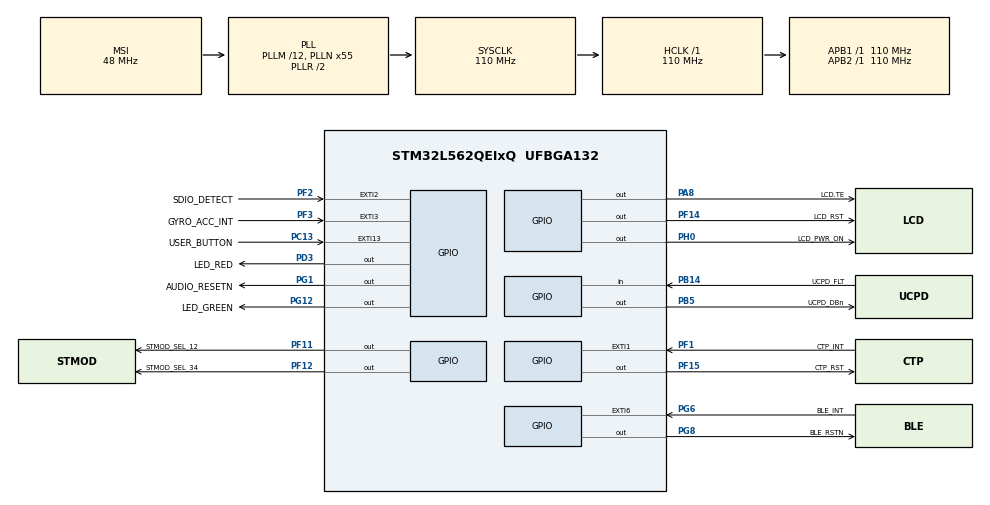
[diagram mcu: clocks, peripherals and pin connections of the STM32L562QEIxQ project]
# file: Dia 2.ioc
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Mcu.Family=STM32L5
Mcu.Name=STM32L562QEIxQ
Mcu.Package=UFBGA132
Mcu.TrustZone=disable
NVIC.EXTI13_IRQn=true\:0\:0\:false\:false\:true\:true\:true\:true
NVIC.PriorityGroup=NVIC_PRIORITYGROUP_3
NVIC.TIM2_IRQn=true\:0\:0\:false\:false\:true\:true\:true\:true
PA10.GPIO_Label=USART1_RX [ST-LINK_VCP_TX]
PA10.Signal=USART1_RX
PA11.Signal=USB_DM
PA12.Signal=USB_DP
PA13\ (JTMS/SWDIO).Signal=DEBUG_JTMS-SWDIO
PA14\ (JTCK/SWCLK).Signal=DEBUG_JTCK-SWCLK
PA15\ (JTDI).Signal=UCPD1_CC1
PA2.Signal=OCTOSPI1_NCS
PA3.Signal=OCTOSPI1_CLK
PA4.GPIO_Label=VBUS_SENSE
PA4.Signal=ADCx_IN9
PA6.Signal=OCTOSPI1_IO3
PA7.Signal=OCTOSPI1_IO2
PA8.GPIO_Label=LCD.TE
PA8.Signal=GPIO_Output
PA9.GPIO_Label=USART1_TX [ST-LINK_VCP_RX]
PA9.Signal=USART1_TX
PB0.Signal=OCTOSPI1_IO1
PB1.Signal=OCTOSPI1_IO0
PB10.Signal=LPUART1_RX
PB11.Signal=LPUART1_TX
PB12.Signal=S_DATAIN1DFSDM1
PB14.GPIO_Label=UCPD_FLT
PB14.Signal=GPIO_Input
PB15.Signal=UCPD1_CC2
PB2.Signal=OCTOSPI1_DQS
PB3\ (JTDO/TRACESWO).Signal=DEBUG_JTDO-SWO
PB5.GPIO_Label=UCPD_DBn
PB5.Signal=GPIO_Output
PB6.Signal=I2C1_SCL
PB7.Signal=I2C1_SDA
PC0.Signal=OCTOSPI1_IO7
PC1.Signal=OCTOSPI1_IO4
PC10.Signal=SDMMC1_D2
PC11.Signal=SDMMC1_D3
PC12.Signal=SDMMC1_CK
PC13.GPIO_Label=USER_BUTTON
PC13.GPIO_ModeDefaultEXTI=GPIO_MODE_IT_FALLING
PC13.Privilege=EXTI_LINE_NPRIV
PC13.Signal=GPXTI13
PC14-OSC32_IN\ (PC14).Signal=RCC_OSC32_IN
PC15-OSC32_OUT\ (PC15).Signal=RCC_OSC32_OUT
PC2.Signal=OCTOSPI1_IO5
PC3.Signal=OCTOSPI1_IO6
PC8.Signal=SDMMC1_D0
PC9.Signal=SDMMC1_D1
PD0.Signal=FMC_D2_DA2
PD1.Signal=FMC_D3_DA3
PD10.Signal=FMC_D15_DA15
PD14.Signal=FMC_D0_DA0
PD15.Signal=FMC_D1_DA1
PD2.Signal=SDMMC1_CMD
PD3.GPIO_Label=LED_RED
PD3.Signal=GPIO_Output
PD4.Signal=FMC_NOE
PD5.Signal=FMC_NWE
PD7.Signal=FMC_NE1
PD8.Signal=FMC_D13_DA13
PD9.Signal=FMC_D14_DA14
PE1.GPIO_Label=LCD_BL_PWM
PE1.Signal=S_TIM17_CH1
PE10.Signal=FMC_D7_DA7
PE11.Signal=FMC_D8_DA8
PE12.Signal=FMC_D9_DA9
PE13.Signal=FMC_D10_DA10
PE14.Signal=FMC_D11_DA11
PE15.Signal=FMC_D12_DA12
PE2.Signal=SAI1_MCLK_A
PE3.Signal=SAI1_SD_B
PE4.Signal=SAI1_FS_A
PE5.Signal=SAI1_SCK_A
PE6.Signal=SAI1_SD_A
PE7.Signal=FMC_D4_DA4
PE8.Signal=FMC_D5_DA5
PE9.Signal=FMC_D6_DA6
PF0.Signal=FMC_A0
PF1.GPIO_Label=CTP_INT
PF1.Signal=GPXTI1
PF11.GPIO_Label=STMOD_SEL_12
PF11.Signal=GPIO_Output
PF12.GPIO_Label=STMOD_SEL_34
PF12.Signal=GPIO_Output
PF14.GPIO_Label=LCD_RST
PF14.Signal=GPIO_Output
PF15.GPIO_Label=CTP_RST
PF15.Signal=GPIO_Output
PF2.GPIO_Label=SDIO_DETECT
PF2.Signal=GPXTI2
PF3.GPIO_Label=GYRO_ACC_INT
PF3.Signal=GPXTI3
PG1.GPIO_Label=AUDIO_RESETN
PG1.Signal=GPIO_Output
PG12.GPIO_Label=LED_GREEN
PG12.Signal=GPIO_Output
PG2.Signal=SPI1_SCK
PG3.Signal=SPI1_MISO
PG4.Signal=SPI1_MOSI
PG5.GPIO_Label=BLE_CSN
PG5.Signal=SPI1_NSS
PG6.GPIO_Label=BLE_INT
PG6.Signal=GPXTI6
PG7.Signal=S_CKOUTDFSDM1
PG8.GPIO_Label=BLE_RSTN
PG8.Signal=GPIO_Output
PH0-OSC_IN\ (PH0).GPIO_Label=LCD_PWR_ON
PH0-OSC_IN\ (PH0).Signal=GPIO_Output
ProjectManager.HeapSize=0x200
ProjectManager.StackSize=0x400
ProjectManager.TargetToolchain=STM32CubeIDE
RCC.ADCFreq_Value=96000000
RCC.AHBFreq_Value=110000000
RCC.APB1Freq_Value=110000000
RCC.APB1TimFreq_Value=110000000
RCC.APB2Freq_Value=110000000
RCC.APB2TimFreq_Value=110000000
RCC.CK48CLockSelection=RCC_USBCLKSOURCE_MSI
RCC.CortexFreq_Value=110000000
RCC.HCLKFreq_Value=110000000
RCC.HSE_VALUE=8000000
RCC.HSI48_VALUE=48000000
RCC.HSI_VALUE=16000000
RCC.LSE_VALUE=32768
RCC.MSIClockRange=RCC_MSIRANGE_11
RCC.MSI_VALUE=48000000
RCC.PLLM=12
RCC.PLLN=55
RCC.PLLSAI1M=4
RCC.PLLSAI1N=48
RCC.PLLSAI1P=RCC_PLLP_DIV17
RCC.PLLSAI1Source=RCC_PLLSAI1SOURCE_HSI
RCC.SDMMCClockSelection=RCC_SDIOCLKSOURCE_CLK48
RCC.SYSCLKFreq_VALUE=110000000
RCC.SYSCLKSource=RCC_SYSCLKSOURCE_PLLCLK
RCC.USBFreq_Value=48000000
RCC.VCOOutputFreq_Value=220000000
SH.ADCx_IN9.0=ADC1_IN9
SH.FMC_A0.0=FMC_A0
SH.FMC_D0_DA0.0=FMC_DA0
SH.FMC_D0_DA0.1=FMC_D0
SH.FMC_D10_DA10.0=FMC_DA10
SH.FMC_D10_DA10.1=FMC_D10
SH.FMC_D11_DA11.0=FMC_DA11
SH.FMC_D11_DA11.1=FMC_D11
SH.FMC_D12_DA12.0=FMC_DA12
SH.FMC_D12_DA12.1=FMC_D12
SH.FMC_D13_DA13.0=FMC_DA13
SH.FMC_D13_DA13.1=FMC_D13
SH.FMC_D14_DA14.0=FMC_DA14
SH.FMC_D14_DA14.1=FMC_D14
SH.FMC_D15_DA15.0=FMC_DA15
SH.FMC_D15_DA15.1=FMC_D15
SH.FMC_D1_DA1.0=FMC_DA1
SH.FMC_D1_DA1.1=FMC_D1
SH.FMC_D2_DA2.0=FMC_DA2
SH.FMC_D2_DA2.1=FMC_D2
SH.FMC_D3_DA3.0=FMC_DA3
SH.FMC_D3_DA3.1=FMC_D3
SH.FMC_D4_DA4.0=FMC_DA4
SH.FMC_D4_DA4.1=FMC_D4
SH.FMC_D5_DA5.0=FMC_DA5
SH.FMC_D5_DA5.1=FMC_D5
SH.FMC_D6_DA6.0=FMC_DA6
SH.FMC_D6_DA6.1=FMC_D6
SH.FMC_D7_DA7.0=FMC_DA7
SH.FMC_D7_DA7.1=FMC_D7
SH.FMC_D8_DA8.0=FMC_DA8
SH.FMC_D8_DA8.1=FMC_D8
SH.FMC_D9_DA9.0=FMC_DA9
SH.FMC_D9_DA9.1=FMC_D9
SH.FMC_NOE.0=FMC_NOE
SH.FMC_NWE.0=FMC_NWE
SH.S_CKOUTDFSDM1.0=DFSDM1_CKOUT
SH.S_DATAIN1DFSDM1.0=DFSDM1_DATIN1
SH.S_TIM17_CH1.0=TIM17_CH1
TIM2.Period=21999
TIM2.Prescaler=9999
VP_ICACHE_VS_ICACHE.Mode=DirectMappedCache
VP_PWR_VS_DBSignals.Mode=DisableDeadBatterySignals
VP_PWR_VS_SECSignals.Mode=Security/Privilege
VP_TIM2_VS_ClockSourceINT.Mode=Internal
board=STM32L562E-DK

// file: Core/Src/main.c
/* USER CODE BEGIN Header */
/**
  ******************************************************************************
  * @file           : main.c
  * @brief          : Main program body
  ******************************************************************************
  * @attention
  *
  * Copyright (c) 2025 STMicroelectronics.
  * All rights reserved.
  *
  * This software is licensed under terms that can be found in the LICENSE file
  * in the root directory of this software component.
  * If no LICENSE file comes with this software, it is provided AS-IS.
  *
  ******************************************************************************
  */
/* USER CODE END Header */
#include "main.h"

TIM_HandleTypeDef htim2;

void SystemClock_Config(void);
static void MX_GPIO_Init(void);
static void MX_ICACHE_Init(void);
static void MX_TIM2_Init(void);

int main(void)
{

  /* MCU Configuration--------------------------------------------------------*/

  /* Reset of all peripherals, Initializes the Flash interface and the Systick. */
  HAL_Init();

  /* Configure the system clock */
  SystemClock_Config();

  /* Initialize all configured peripherals */
  MX_GPIO_Init();
  MX_ICACHE_Init();
  MX_TIM2_Init();
  /* USER CODE BEGIN 2 */
  if (HAL_TIM_Base_Start_IT(&htim2) != HAL_OK) {
    Error_Handler();
  }
  /* USER CODE END 2 */

  /* Infinite loop */
  while (1)
  {

  }
}
void HAL_GPIO_EXTI_Falling_Callback(uint16_t GPIO_Pin)
{
    if (GPIO_Pin == USER_BUTTON_Pin) {
        HAL_GPIO_TogglePin(LED_RED_GPIO_Port, LED_RED_Pin); // LED2 enciende/apaga
    }
}
void HAL_TIM_PeriodElapsedCallback(TIM_HandleTypeDef *htim){
	if(htim->Instance==TIM2){
		HAL_GPIO_TogglePin(LED_GREEN_GPIO_Port, LED_GREEN_Pin);
	}
}
void SystemClock_Config(void)
{
  RCC_OscInitTypeDef RCC_OscInitStruct = {0};
  RCC_ClkInitTypeDef RCC_ClkInitStruct = {0};

  /** Configure the main internal regulator output voltage
  */
  if (HAL_PWREx_ControlVoltageScaling(PWR_REGULATOR_VOLTAGE_SCALE0) != HAL_OK)
  {
    Error_Handler();
  }

  /** Initializes the RCC Oscillators according to the specified parameters
  * in the RCC_OscInitTypeDef structure.
  */
  RCC_OscInitStruct.OscillatorType = RCC_OSCILLATORTYPE_MSI;
  RCC_OscInitStruct.MSIState = RCC_MSI_ON;
  RCC_OscInitStruct.MSICalibrationValue = RCC_MSICALIBRATION_DEFAULT;
  RCC_OscInitStruct.MSIClockRange = RCC_MSIRANGE_11;
  RCC_OscInitStruct.PLL.PLLState = RCC_PLL_ON;
  RCC_OscInitStruct.PLL.PLLSource = RCC_PLLSOURCE_MSI;
  RCC_OscInitStruct.PLL.PLLM = 12;
  RCC_OscInitStruct.PLL.PLLN = 55;
  RCC_OscInitStruct.PLL.PLLP = RCC_PLLP_DIV7;
  RCC_OscInitStruct.PLL.PLLQ = RCC_PLLQ_DIV2;
  RCC_OscInitStruct.PLL.PLLR = RCC_PLLR_DIV2;
  if (HAL_RCC_OscConfig(&RCC_OscInitStruct) != HAL_OK)
  {
    Error_Handler();
  }

  /** Initializes the CPU, AHB and APB buses clocks
  */
  RCC_ClkInitStruct.ClockType = RCC_CLOCKTYPE_HCLK|RCC_CLOCKTYPE_SYSCLK
                              |RCC_CLOCKTYPE_PCLK1|RCC_CLOCKTYPE_PCLK2;
  RCC_ClkInitStruct.SYSCLKSource = RCC_SYSCLKSOURCE_PLLCLK;
  RCC_ClkInitStruct.AHBCLKDivider = RCC_SYSCLK_DIV1;
  RCC_ClkInitStruct.APB1CLKDivider = RCC_HCLK_DIV1;
  RCC_ClkInitStruct.APB2CLKDivider = RCC_HCLK_DIV1;

  if (HAL_RCC_ClockConfig(&RCC_ClkInitStruct, FLASH_LATENCY_5) != HAL_OK)
  {
    Error_Handler();
  }
}

static void MX_ICACHE_Init(void)
{

  /** Enable instruction cache in 1-way (direct mapped cache)
  */
  if (HAL_ICACHE_ConfigAssociativityMode(ICACHE_1WAY) != HAL_OK)
  {
    Error_Handler();
  }
  if (HAL_ICACHE_Enable() != HAL_OK)
  {
    Error_Handler();
  }

}

static void MX_TIM2_Init(void)
{

  TIM_ClockConfigTypeDef sClockSourceConfig = {0};
  TIM_MasterConfigTypeDef sMasterConfig = {0};

  htim2.Instance = TIM2;
  htim2.Init.Prescaler = 9999;
  htim2.Init.CounterMode = TIM_COUNTERMODE_UP;
  htim2.Init.Period = 21999;
  htim2.Init.ClockDivision = TIM_CLOCKDIVISION_DIV1;
  htim2.Init.AutoReloadPreload = TIM_AUTORELOAD_PRELOAD_DISABLE;
  if (HAL_TIM_Base_Init(&htim2) != HAL_OK)
  {
    Error_Handler();
  }
  sClockSourceConfig.ClockSource = TIM_CLOCKSOURCE_INTERNAL;
  if (HAL_TIM_ConfigClockSource(&htim2, &sClockSourceConfig) != HAL_OK)
  {
    Error_Handler();
  }
  sMasterConfig.MasterOutputTrigger = TIM_TRGO_RESET;
  sMasterConfig.MasterSlaveMode = TIM_MASTERSLAVEMODE_DISABLE;
  if (HAL_TIMEx_MasterConfigSynchronization(&htim2, &sMasterConfig) != HAL_OK)
  {
    Error_Handler();
  }

}

static void MX_GPIO_Init(void)
{
  GPIO_InitTypeDef GPIO_InitStruct = {0};

  /* GPIO Ports Clock Enable */
  __HAL_RCC_GPIOE_CLK_ENABLE();
  __HAL_RCC_GPIOB_CLK_ENABLE();
  __HAL_RCC_GPIOG_CLK_ENABLE();
  HAL_PWREx_EnableVddIO2();
  __HAL_RCC_GPIOD_CLK_ENABLE();
  __HAL_RCC_GPIOC_CLK_ENABLE();
  __HAL_RCC_GPIOA_CLK_ENABLE();
  __HAL_RCC_GPIOF_CLK_ENABLE();
  __HAL_RCC_GPIOH_CLK_ENABLE();

  /*Configure GPIO pin Output Level */
  HAL_GPIO_WritePin(GPIOG, LED_GREEN_Pin|BLE_RSTN_Pin|AUDIO_RESETN_Pin, GPIO_PIN_RESET);

  /*Configure GPIO pin Output Level */
  HAL_GPIO_WritePin(LED_RED_GPIO_Port, LED_RED_Pin, GPIO_PIN_RESET);

  /*Configure GPIO pin Output Level */
  HAL_GPIO_WritePin(UCPD_DBn_GPIO_Port, UCPD_DBn_Pin, GPIO_PIN_RESET);

  /*Configure GPIO pin Output Level */
  HAL_GPIO_WritePin(LCD_TE_GPIO_Port, LCD_TE_Pin, GPIO_PIN_RESET);

  /*Configure GPIO pin Output Level */
  HAL_GPIO_WritePin(LCD_PWR_ON_GPIO_Port, LCD_PWR_ON_Pin, GPIO_PIN_RESET);

  /*Configure GPIO pin Output Level */
  HAL_GPIO_WritePin(GPIOF, LCD_RST_Pin|STMOD_SEL_12_Pin|STMOD_SEL_34_Pin|CTP_RST_Pin, GPIO_PIN_RESET);

  /*Configure GPIO pins : PE5 PE3 PE4 PE2
                           PE6 */
  GPIO_InitStruct.Pin = GPIO_PIN_5|GPIO_PIN_3|GPIO_PIN_4|GPIO_PIN_2
                          |GPIO_PIN_6;
  GPIO_InitStruct.Mode = GPIO_MODE_AF_PP;
  GPIO_InitStruct.Pull = GPIO_NOPULL;
  GPIO_InitStruct.Speed = GPIO_SPEED_FREQ_LOW;
  GPIO_InitStruct.Alternate = GPIO_AF13_SAI1;
  HAL_GPIO_Init(GPIOE, &GPIO_InitStruct);

  /*Configure GPIO pin : LCD_BL_PWM_Pin */
  GPIO_InitStruct.Pin = LCD_BL_PWM_Pin;
  GPIO_InitStruct.Mode = GPIO_MODE_AF_PP;
  GPIO_InitStruct.Pull = GPIO_NOPULL;
  GPIO_InitStruct.Speed = GPIO_SPEED_FREQ_LOW;
  GPIO_InitStruct.Alternate = GPIO_AF14_TIM17;
  HAL_GPIO_Init(LCD_BL_PWM_GPIO_Port, &GPIO_InitStruct);

  /*Configure GPIO pins : PB6 PB7 */
  GPIO_InitStruct.Pin = GPIO_PIN_6|GPIO_PIN_7;
  GPIO_InitStruct.Mode = GPIO_MODE_AF_OD;
  GPIO_InitStruct.Pull = GPIO_NOPULL;
  GPIO_InitStruct.Speed = GPIO_SPEED_FREQ_LOW;
  GPIO_InitStruct.Alternate = GPIO_AF4_I2C1;
  HAL_GPIO_Init(GPIOB, &GPIO_InitStruct);

  /*Configure GPIO pins : LED_GREEN_Pin BLE_RSTN_Pin AUDIO_RESETN_Pin */
  GPIO_InitStruct.Pin = LED_GREEN_Pin|BLE_RSTN_Pin|AUDIO_RESETN_Pin;
  GPIO_InitStruct.Mode = GPIO_MODE_OUTPUT_PP;
  GPIO_InitStruct.Pull = GPIO_NOPULL;
  GPIO_InitStruct.Speed = GPIO_SPEED_FREQ_LOW;
  HAL_GPIO_Init(GPIOG, &GPIO_InitStruct);

  /*Configure GPIO pins : PD5 PD4 PD1 PD0
                           PD7 PD14 PD15 PD9
                           PD8 PD10 */
  GPIO_InitStruct.Pin = GPIO_PIN_5|GPIO_PIN_4|GPIO_PIN_1|GPIO_PIN_0
                          |GPIO_PIN_7|GPIO_PIN_14|GPIO_PIN_15|GPIO_PIN_9
                          |GPIO_PIN_8|GPIO_PIN_10;
  GPIO_InitStruct.Mode = GPIO_MODE_AF_PP;
  GPIO_InitStruct.Pull = GPIO_NOPULL;
  GPIO_InitStruct.Speed = GPIO_SPEED_FREQ_VERY_HIGH;
  GPIO_InitStruct.Alternate = GPIO_AF12_FMC;
  HAL_GPIO_Init(GPIOD, &GPIO_InitStruct);

  /*Configure GPIO pin : PD2 */
  GPIO_InitStruct.Pin = GPIO_PIN_2;
  GPIO_InitStruct.Mode = GPIO_MODE_AF_PP;
  GPIO_InitStruct.Pull = GPIO_NOPULL;
  GPIO_InitStruct.Speed = GPIO_SPEED_FREQ_VERY_HIGH;
  GPIO_InitStruct.Alternate = GPIO_AF12_SDMMC1;
  HAL_GPIO_Init(GPIOD, &GPIO_InitStruct);

  /*Configure GPIO pins : PC11 PC12 PC10 PC9
                           PC8 */
  GPIO_InitStruct.Pin = GPIO_PIN_11|GPIO_PIN_12|GPIO_PIN_10|GPIO_PIN_9
                          |GPIO_PIN_8;
  GPIO_InitStruct.Mode = GPIO_MODE_AF_PP;
  GPIO_InitStruct.Pull = GPIO_NOPULL;
  GPIO_InitStruct.Speed = GPIO_SPEED_FREQ_VERY_HIGH;
  GPIO_InitStruct.Alternate = GPIO_AF12_SDMMC1;
  HAL_GPIO_Init(GPIOC, &GPIO_InitStruct);

  /*Configure GPIO pins : PA15 VBUS_SENSE_Pin */
  GPIO_InitStruct.Pin = GPIO_PIN_15|VBUS_SENSE_Pin;
  GPIO_InitStruct.Mode = GPIO_MODE_ANALOG;
  GPIO_InitStruct.Pull = GPIO_NOPULL;
  HAL_GPIO_Init(GPIOA, &GPIO_InitStruct);

  /*Configure GPIO pins : PA12 PA11 */
  GPIO_InitStruct.Pin = GPIO_PIN_12|GPIO_PIN_11;
  GPIO_InitStruct.Mode = GPIO_MODE_AF_PP;
  GPIO_InitStruct.Pull = GPIO_NOPULL;
  GPIO_InitStruct.Speed = GPIO_SPEED_FREQ_LOW;
  GPIO_InitStruct.Alternate = GPIO_AF10_USB;
  HAL_GPIO_Init(GPIOA, &GPIO_InitStruct);

  /*Configure GPIO pin : USER_BUTTON_Pin */
  GPIO_InitStruct.Pin = USER_BUTTON_Pin;
  GPIO_InitStruct.Mode = GPIO_MODE_IT_FALLING;
  GPIO_InitStruct.Pull = GPIO_NOPULL;
  HAL_GPIO_Init(USER_BUTTON_GPIO_Port, &GPIO_InitStruct);

  /*Configure GPIO pin : LED_RED_Pin */
  GPIO_InitStruct.Pin = LED_RED_Pin;
  GPIO_InitStruct.Mode = GPIO_MODE_OUTPUT_PP;
  GPIO_InitStruct.Pull = GPIO_NOPULL;
  GPIO_InitStruct.Speed = GPIO_SPEED_FREQ_LOW;
  HAL_GPIO_Init(LED_RED_GPIO_Port, &GPIO_InitStruct);

  /*Configure GPIO pin : PF0 */
  GPIO_InitStruct.Pin = GPIO_PIN_0;
  GPIO_InitStruct.Mode = GPIO_MODE_AF_PP;
  GPIO_InitStruct.Pull = GPIO_NOPULL;
  GPIO_InitStruct.Speed = GPIO_SPEED_FREQ_VERY_HIGH;
  GPIO_InitStruct.Alternate = GPIO_AF12_FMC;
  HAL_GPIO_Init(GPIOF, &GPIO_InitStruct);

  /*Configure GPIO pins : GYRO_ACC_INT_Pin SDIO_DETECT_Pin CTP_INT_Pin */
  GPIO_InitStruct.Pin = GYRO_ACC_INT_Pin|SDIO_DETECT_Pin|CTP_INT_Pin;
  GPIO_InitStruct.Mode = GPIO_MODE_IT_RISING;
  GPIO_InitStruct.Pull = GPIO_NOPULL;
  HAL_GPIO_Init(GPIOF, &GPIO_InitStruct);

  /*Configure GPIO pin : UCPD_DBn_Pin */
  GPIO_InitStruct.Pin = UCPD_DBn_Pin;
  GPIO_InitStruct.Mode = GPIO_MODE_OUTPUT_PP;
  GPIO_InitStruct.Pull = GPIO_NOPULL;
  GPIO_InitStruct.Speed = GPIO_SPEED_FREQ_LOW;
  HAL_GPIO_Init(UCPD_DBn_GPIO_Port, &GPIO_InitStruct);

  /*Configure GPIO pins : USART1_TX_Pin USART1_RX_Pin */
  GPIO_InitStruct.Pin = USART1_TX_Pin|USART1_RX_Pin;
  GPIO_InitStruct.Mode = GPIO_MODE_AF_PP;
  GPIO_InitStruct.Pull = GPIO_NOPULL;
  GPIO_InitStruct.Speed = GPIO_SPEED_FREQ_LOW;
  GPIO_InitStruct.Alternate = GPIO_AF7_USART1;
  HAL_GPIO_Init(GPIOA, &GPIO_InitStruct);

  /*Configure GPIO pin : LCD_TE_Pin */
  GPIO_InitStruct.Pin = LCD_TE_Pin;
  GPIO_InitStruct.Mode = GPIO_MODE_OUTPUT_PP;
  GPIO_InitStruct.Pull = GPIO_NOPULL;
  GPIO_InitStruct.Speed = GPIO_SPEED_FREQ_LOW;
  HAL_GPIO_Init(LCD_TE_GPIO_Port, &GPIO_InitStruct);

  /*Configure GPIO pin : LCD_PWR_ON_Pin */
  GPIO_InitStruct.Pin = LCD_PWR_ON_Pin;
  GPIO_InitStruct.Mode = GPIO_MODE_OUTPUT_PP;
  GPIO_InitStruct.Pull = GPIO_NOPULL;
  GPIO_InitStruct.Speed = GPIO_SPEED_FREQ_LOW;
  HAL_GPIO_Init(LCD_PWR_ON_GPIO_Port, &GPIO_InitStruct);

  /*Configure GPIO pins : PC2 PC3 PC1 */
  GPIO_InitStruct.Pin = GPIO_PIN_2|GPIO_PIN_3|GPIO_PIN_1;
  GPIO_InitStruct.Mode = GPIO_MODE_AF_PP;
  GPIO_InitStruct.Pull = GPIO_NOPULL;
  GPIO_InitStruct.Speed = GPIO_SPEED_FREQ_VERY_HIGH;
  GPIO_InitStruct.Alternate = GPIO_AF10_OCTOSPI1;
  HAL_GPIO_Init(GPIOC, &GPIO_InitStruct);

  /*Configure GPIO pin : BLE_INT_Pin */
  GPIO_InitStruct.Pin = BLE_INT_Pin;
  GPIO_InitStruct.Mode = GPIO_MODE_IT_RISING;
  GPIO_InitStruct.Pull = GPIO_NOPULL;
  HAL_GPIO_Init(BLE_INT_GPIO_Port, &GPIO_InitStruct);

  /*Configure GPIO pin : PG7 */
  GPIO_InitStruct.Pin = GPIO_PIN_7;
  GPIO_InitStruct.Mode = GPIO_MODE_AF_PP;
  GPIO_InitStruct.Pull = GPIO_NOPULL;
  GPIO_InitStruct.Speed = GPIO_SPEED_FREQ_LOW;
  GPIO_InitStruct.Alternate = GPIO_AF6_DFSDM1;
  HAL_GPIO_Init(GPIOG, &GPIO_InitStruct);

  /*Configure GPIO pins : PG4 PG2 PG3 BLE_CSN_Pin */
  GPIO_InitStruct.Pin = GPIO_PIN_4|GPIO_PIN_2|GPIO_PIN_3|BLE_CSN_Pin;
  GPIO_InitStruct.Mode = GPIO_MODE_AF_PP;
  GPIO_InitStruct.Pull = GPIO_NOPULL;
  GPIO_InitStruct.Speed = GPIO_SPEED_FREQ_LOW;
  GPIO_InitStruct.Alternate = GPIO_AF5_SPI1;
  HAL_GPIO_Init(GPIOG, &GPIO_InitStruct);

  /*Configure GPIO pin : PC0 */
  GPIO_InitStruct.Pin = GPIO_PIN_0;
  GPIO_InitStruct.Mode = GPIO_MODE_AF_PP;
  GPIO_InitStruct.Pull = GPIO_NOPULL;
  GPIO_InitStruct.Speed = GPIO_SPEED_FREQ_VERY_HIGH;
  GPIO_InitStruct.Alternate = GPIO_AF3_OCTOSPI1;
  HAL_GPIO_Init(GPIOC, &GPIO_InitStruct);

  /*Configure GPIO pins : LCD_RST_Pin STMOD_SEL_12_Pin STMOD_SEL_34_Pin CTP_RST_Pin */
  GPIO_InitStruct.Pin = LCD_RST_Pin|STMOD_SEL_12_Pin|STMOD_SEL_34_Pin|CTP_RST_Pin;
  GPIO_InitStruct.Mode = GPIO_MODE_OUTPUT_PP;
  GPIO_InitStruct.Pull = GPIO_NOPULL;
  GPIO_InitStruct.Speed = GPIO_SPEED_FREQ_LOW;
  HAL_GPIO_Init(GPIOF, &GPIO_InitStruct);

  /*Configure GPIO pins : PE8 PE10 PE12 PE7
                           PE14 PE11 PE15 PE9
                           PE13 */
  GPIO_InitStruct.Pin = GPIO_PIN_8|GPIO_PIN_10|GPIO_PIN_12|GPIO_PIN_7
                          |GPIO_PIN_14|GPIO_PIN_11|GPIO_PIN_15|GPIO_PIN_9
                          |GPIO_PIN_13;
  GPIO_InitStruct.Mode = GPIO_MODE_AF_PP;
  GPIO_InitStruct.Pull = GPIO_NOPULL;
  GPIO_InitStruct.Speed = GPIO_SPEED_FREQ_VERY_HIGH;
  GPIO_InitStruct.Alternate = GPIO_AF12_FMC;
  HAL_GPIO_Init(GPIOE, &GPIO_InitStruct);

  /*Configure GPIO pins : PA2 PA7 PA3 PA6 */
  GPIO_InitStruct.Pin = GPIO_PIN_2|GPIO_PIN_7|GPIO_PIN_3|GPIO_PIN_6;
  GPIO_InitStruct.Mode = GPIO_MODE_AF_PP;
  GPIO_InitStruct.Pull = GPIO_NOPULL;
  GPIO_InitStruct.Speed = GPIO_SPEED_FREQ_VERY_HIGH;
  GPIO_InitStruct.Alternate = GPIO_AF10_OCTOSPI1;
  HAL_GPIO_Init(GPIOA, &GPIO_InitStruct);

  /*Configure GPIO pins : PB2 PB1 PB0 */
  GPIO_InitStruct.Pin = GPIO_PIN_2|GPIO_PIN_1|GPIO_PIN_0;
  GPIO_InitStruct.Mode = GPIO_MODE_AF_PP;
  GPIO_InitStruct.Pull = GPIO_NOPULL;
  GPIO_InitStruct.Speed = GPIO_SPEED_FREQ_VERY_HIGH;
  GPIO_InitStruct.Alternate = GPIO_AF10_OCTOSPI1;
  HAL_GPIO_Init(GPIOB, &GPIO_InitStruct);

  /*Configure GPIO pins : PB10 PB11 */
  GPIO_InitStruct.Pin = GPIO_PIN_10|GPIO_PIN_11;
  GPIO_InitStruct.Mode = GPIO_MODE_AF_PP;
  GPIO_InitStruct.Pull = GPIO_NOPULL;
  GPIO_InitStruct.Speed = GPIO_SPEED_FREQ_LOW;
  GPIO_InitStruct.Alternate = GPIO_AF8_LPUART1;
  HAL_GPIO_Init(GPIOB, &GPIO_InitStruct);

  /*Configure GPIO pin : UCPD_FLT_Pin */
  GPIO_InitStruct.Pin = UCPD_FLT_Pin;
  GPIO_InitStruct.Mode = GPIO_MODE_INPUT;
  GPIO_InitStruct.Pull = GPIO_NOPULL;
  HAL_GPIO_Init(UCPD_FLT_GPIO_Port, &GPIO_InitStruct);

  /*Configure GPIO pin : PB15 */
  GPIO_InitStruct.Pin = GPIO_PIN_15;
  GPIO_InitStruct.Mode = GPIO_MODE_ANALOG;
  GPIO_InitStruct.Pull = GPIO_NOPULL;
  HAL_GPIO_Init(GPIOB, &GPIO_InitStruct);

  /*Configure GPIO pin : PB12 */
  GPIO_InitStruct.Pin = GPIO_PIN_12;
  GPIO_InitStruct.Mode = GPIO_MODE_AF_PP;
  GPIO_InitStruct.Pull = GPIO_NOPULL;
  GPIO_InitStruct.Speed = GPIO_SPEED_FREQ_LOW;
  GPIO_InitStruct.Alternate = GPIO_AF6_DFSDM1;
  HAL_GPIO_Init(GPIOB, &GPIO_InitStruct);

  /* EXTI interrupt init*/
  HAL_NVIC_SetPriority(EXTI13_IRQn, 0, 0);
  HAL_NVIC_EnableIRQ(EXTI13_IRQn);

}

void Error_Handler(void)
{
  __disable_irq();
  while (1)
  {
  }
}
